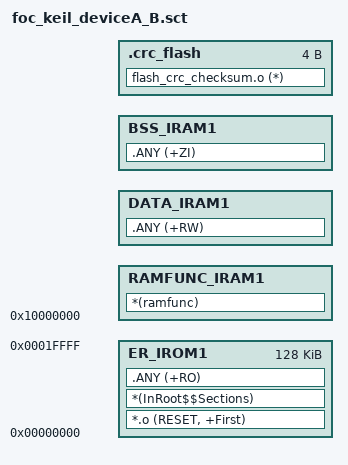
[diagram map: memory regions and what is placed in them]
; *************************************************************
; *** Scatter-Loading Description File generated by uVision ***
; *************************************************************

LR_IROM1 0x00000000 0x00020000  {    ; load region size_region
  ER_IROM1 0x00000000 0x00020000  {  ; load address = execution address
    *.o (RESET, +First)
    *(InRoot$$Sections)
    .ANY (+RO)
  }

  RAMFUNC_IRAM1 0x10000000  {  ; ramfuncs
    *(ramfunc)  
  }
  
  DATA_IRAM1 (0x20000000 + ImageLength(RAMFUNC_IRAM1)) {  ; data
    .ANY (+RW)
  }
  
  BSS_IRAM1 +0 {  ; bss
    .ANY (+ZI)
  }
}

LR_IROM1_END +0 0x4
{
  .crc_flash +0 0x4
  {
    flash_crc_checksum.o (*)
  }
}

ScatterAssert((ImageLength(RAMFUNC_IRAM1) + ImageLength(DATA_IRAM1) + ImageLength(BSS_IRAM1)) < 0x8000) ; Check used ram
